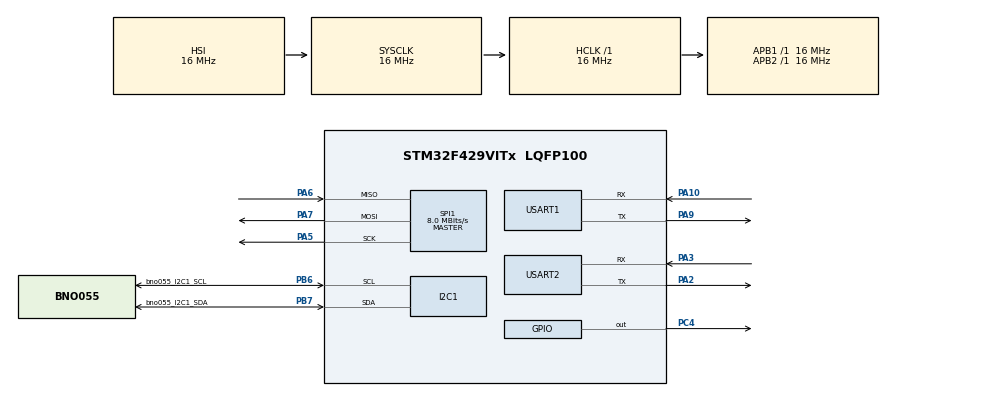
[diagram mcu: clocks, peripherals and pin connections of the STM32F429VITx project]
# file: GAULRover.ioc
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Dma.I2C1_RX.0.Direction=DMA_PERIPH_TO_MEMORY
Dma.I2C1_RX.0.FIFOMode=DMA_FIFOMODE_DISABLE
Dma.I2C1_RX.0.Instance=DMA1_Stream0
Dma.I2C1_RX.0.MemDataAlignment=DMA_MDATAALIGN_BYTE
Dma.I2C1_RX.0.MemInc=DMA_MINC_ENABLE
Dma.I2C1_RX.0.Mode=DMA_NORMAL
Dma.I2C1_RX.0.PeriphDataAlignment=DMA_PDATAALIGN_BYTE
Dma.I2C1_RX.0.PeriphInc=DMA_PINC_DISABLE
Dma.I2C1_RX.0.Priority=DMA_PRIORITY_LOW
Dma.I2C1_TX.1.Direction=DMA_MEMORY_TO_PERIPH
Dma.I2C1_TX.1.FIFOMode=DMA_FIFOMODE_DISABLE
Dma.I2C1_TX.1.Instance=DMA1_Stream6
Dma.I2C1_TX.1.MemDataAlignment=DMA_MDATAALIGN_BYTE
Dma.I2C1_TX.1.MemInc=DMA_MINC_ENABLE
Dma.I2C1_TX.1.Mode=DMA_NORMAL
Dma.I2C1_TX.1.PeriphDataAlignment=DMA_PDATAALIGN_BYTE
Dma.I2C1_TX.1.PeriphInc=DMA_PINC_DISABLE
Dma.I2C1_TX.1.Priority=DMA_PRIORITY_LOW
Dma.Request0=I2C1_RX
Dma.Request1=I2C1_TX
Dma.Request2=USART1_RX
Dma.Request3=USART1_TX
Dma.USART1_RX.2.Direction=DMA_PERIPH_TO_MEMORY
Dma.USART1_RX.2.FIFOMode=DMA_FIFOMODE_DISABLE
Dma.USART1_RX.2.Instance=DMA2_Stream2
Dma.USART1_RX.2.MemDataAlignment=DMA_MDATAALIGN_BYTE
Dma.USART1_RX.2.MemInc=DMA_MINC_ENABLE
Dma.USART1_RX.2.Mode=DMA_NORMAL
Dma.USART1_RX.2.PeriphDataAlignment=DMA_PDATAALIGN_BYTE
Dma.USART1_RX.2.PeriphInc=DMA_PINC_DISABLE
Dma.USART1_RX.2.Priority=DMA_PRIORITY_LOW
Dma.USART1_TX.3.Direction=DMA_MEMORY_TO_PERIPH
Dma.USART1_TX.3.FIFOMode=DMA_FIFOMODE_DISABLE
Dma.USART1_TX.3.Instance=DMA2_Stream7
Dma.USART1_TX.3.MemDataAlignment=DMA_MDATAALIGN_BYTE
Dma.USART1_TX.3.MemInc=DMA_MINC_ENABLE
Dma.USART1_TX.3.Mode=DMA_NORMAL
Dma.USART1_TX.3.PeriphDataAlignment=DMA_PDATAALIGN_BYTE
Dma.USART1_TX.3.PeriphInc=DMA_PINC_DISABLE
Dma.USART1_TX.3.Priority=DMA_PRIORITY_LOW
Mcu.Family=STM32F4
Mcu.Name=STM32F429VITx
Mcu.Package=LQFP100
NVIC.DMA1_Stream0_IRQn=true\:0\:0\:false\:false\:true\:false\:true\:true
NVIC.DMA1_Stream6_IRQn=true\:0\:0\:false\:false\:true\:false\:true\:true
NVIC.DMA2_Stream2_IRQn=true\:0\:0\:false\:false\:true\:false\:true\:true
NVIC.DMA2_Stream7_IRQn=true\:0\:0\:false\:false\:true\:false\:true\:true
NVIC.PriorityGroup=NVIC_PRIORITYGROUP_4
NVIC.USART1_IRQn=true\:0\:0\:false\:false\:true\:true\:true\:true
PA10.Mode=Asynchronous
PA10.Signal=USART1_RX
PA13.Mode=Serial_Wire
PA13.Signal=SYS_JTMS-SWDIO
PA14.Mode=Serial_Wire
PA14.Signal=SYS_JTCK-SWCLK
PA2.Mode=Asynchronous
PA2.Signal=USART2_TX
PA3.Mode=Asynchronous
PA3.Signal=USART2_RX
PA5.Mode=Full_Duplex_Master
PA5.Signal=SPI1_SCK
PA6.Mode=Full_Duplex_Master
PA6.Signal=SPI1_MISO
PA7.Mode=Full_Duplex_Master
PA7.Signal=SPI1_MOSI
PA9.Mode=Asynchronous
PA9.Signal=USART1_TX
PB6.GPIO_Label=bno055_I2C1_SCL
PB6.Mode=I2C
PB6.Signal=I2C1_SCL
PB7.GPIO_Label=bno055_I2C1_SDA
PB7.Mode=I2C
PB7.Signal=I2C1_SDA
PC4.Signal=GPIO_Output
ProjectManager.HeapSize=0x200
ProjectManager.StackSize=0x400
ProjectManager.TargetToolchain=STM32CubeIDE
RCC.AHBFreq_Value=16000000
RCC.APB1Freq_Value=16000000
RCC.APB1TimFreq_Value=16000000
RCC.APB2Freq_Value=16000000
RCC.APB2TimFreq_Value=16000000
RCC.CortexFreq_Value=16000000
RCC.HCLKFreq_Value=16000000
RCC.HSE_VALUE=25000000
RCC.HSI_VALUE=16000000
RCC.LSE_VALUE=32768
RCC.SYSCLKFreq_VALUE=16000000
RCC.VCOOutputFreq_Value=192000000
SPI1.CalculateBaudRate=8.0 MBits/s
SPI1.Direction=SPI_DIRECTION_2LINES
SPI1.Mode=SPI_MODE_MASTER
SPI1.VirtualType=VM_MASTER
USART1.VirtualMode=VM_ASYNC
USART2.VirtualMode=VM_ASYNC
VP_FATFS_VS_Generic.Mode=User_defined
board=custom

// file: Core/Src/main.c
/* USER CODE BEGIN Header */
/**
  ******************************************************************************
  * @file           : main.c
  * @brief          : Main program body
  ******************************************************************************
  * @attention
  *
  * Copyright (c) 2026 STMicroelectronics.
  * All rights reserved.
  *
  * This software is licensed under terms that can be found in the LICENSE file
  * in the root directory of this software component.
  * If no LICENSE file comes with this software, it is provided AS-IS.
  *
  ******************************************************************************
  */
/* USER CODE END Header */
#include "main.h"
#include "dma.h"
#include "fatfs.h"
#include "i2c.h"
#include "spi.h"
#include "usart.h"
#include "gpio.h"

/* USER CODE BEGIN Includes */

#include "tfluna/tfluna.h"
#include "map/hardware_map.h"
#include "sd/sd.h"

/* USER CODE END Includes */

void SystemClock_Config(void);

int main(void)
{

  /* MCU Configuration--------------------------------------------------------*/

  /* Reset of all peripherals, Initializes the Flash interface and the Systick. */
  HAL_Init();

  /* Configure the system clock */
  SystemClock_Config();

  /* Initialize all configured peripherals */
  MX_GPIO_Init();
  MX_DMA_Init();
  MX_I2C1_Init();
  MX_USART1_UART_Init();
  MX_SPI1_Init();
  MX_FATFS_Init();
  MX_USART2_UART_Init();
  /* USER CODE BEGIN 2 */
  sd_Init();
  sd_Test();
  /* USER CODE END 2 */

  /* Infinite loop */
  while (1)
  {

  }
}

void SystemClock_Config(void)
{
  RCC_OscInitTypeDef RCC_OscInitStruct = {0};
  RCC_ClkInitTypeDef RCC_ClkInitStruct = {0};

  /** Configure the main internal regulator output voltage
  */
  __HAL_RCC_PWR_CLK_ENABLE();
  __HAL_PWR_VOLTAGESCALING_CONFIG(PWR_REGULATOR_VOLTAGE_SCALE3);

  /** Initializes the RCC Oscillators according to the specified parameters
  * in the RCC_OscInitTypeDef structure.
  */
  RCC_OscInitStruct.OscillatorType = RCC_OSCILLATORTYPE_HSI;
  RCC_OscInitStruct.HSIState = RCC_HSI_ON;
  RCC_OscInitStruct.HSICalibrationValue = RCC_HSICALIBRATION_DEFAULT;
  RCC_OscInitStruct.PLL.PLLState = RCC_PLL_NONE;
  if (HAL_RCC_OscConfig(&RCC_OscInitStruct) != HAL_OK)
  {
    Error_Handler();
  }

  /** Initializes the CPU, AHB and APB buses clocks
  */
  RCC_ClkInitStruct.ClockType = RCC_CLOCKTYPE_HCLK|RCC_CLOCKTYPE_SYSCLK
                              |RCC_CLOCKTYPE_PCLK1|RCC_CLOCKTYPE_PCLK2;
  RCC_ClkInitStruct.SYSCLKSource = RCC_SYSCLKSOURCE_HSI;
  RCC_ClkInitStruct.AHBCLKDivider = RCC_SYSCLK_DIV1;
  RCC_ClkInitStruct.APB1CLKDivider = RCC_HCLK_DIV1;
  RCC_ClkInitStruct.APB2CLKDivider = RCC_HCLK_DIV1;

  if (HAL_RCC_ClockConfig(&RCC_ClkInitStruct, FLASH_LATENCY_0) != HAL_OK)
  {
    Error_Handler();
  }
}

/* USER CODE BEGIN 4 */

void HAL_UART_RxCpltCallback(UART_HandleTypeDef *huart)
{
	if(huart == TFLUNA_UART)
	{
		tfluna_UART_RxCallback();
	}
}

/* USER CODE END 4 */

void Error_Handler(void)
{
  __disable_irq();
  while (1)
  {
  }
}
